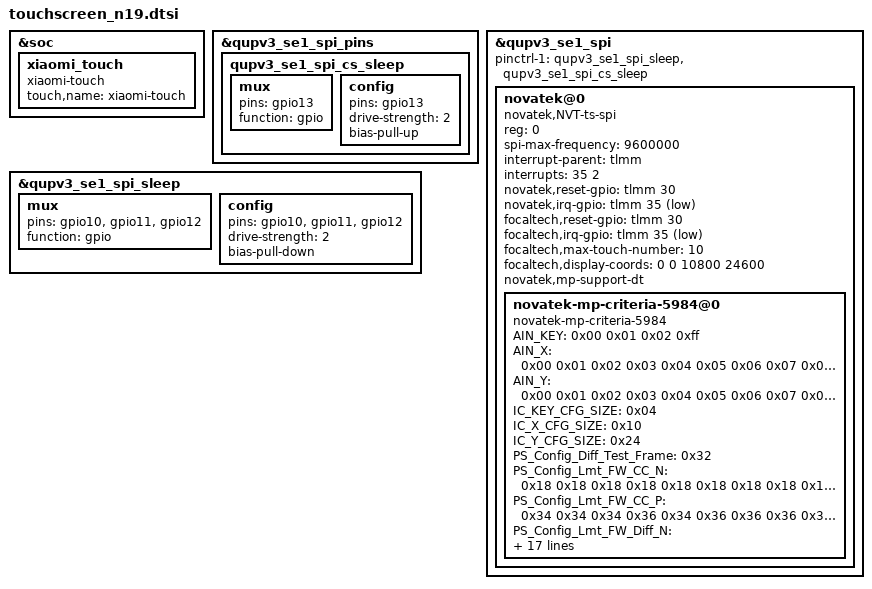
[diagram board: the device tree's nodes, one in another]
// SPDX-License-Identifier: BSD-3-Clause

&soc {
	xiaomi_touch {
		status = "ok";
		compatible = "xiaomi-touch";
		touch,name = "xiaomi-touch";
	};
};

&qupv3_se1_spi_pins {
	qupv3_se1_spi_cs_sleep: qupv3_se1_spi_cs_sleep {
		mux {
			pins = "gpio13";
			function = "gpio";
		};

		config {
			pins = "gpio13";
			drive-strength = <2>;
			bias-pull-up;
		};
	};
};

&qupv3_se1_spi_sleep {
	mux {
		pins = "gpio10", "gpio11", "gpio12";
		function = "gpio";
	};

	config {
		pins = "gpio10", "gpio11", "gpio12";
		drive-strength = <2>;
		bias-pull-down;
	};
};

/*
 * Stock has separate novatek@0 and focaltech@1 nodes, but both ICs sit on
 * CS0 and share the reset and interrupt GPIOs. Use one node so only one
 * driver binds at a time.
 */
&qupv3_se1_spi {
	#address-cells = <1>;
	#size-cells = <0>;
	pinctrl-1 = <&qupv3_se1_spi_sleep>, <&qupv3_se1_spi_cs_sleep>;
	status = "ok";

	novatek@0 {
		compatible = "novatek,NVT-ts-spi", "focaltech,fts";
		reg = <0>;
		status = "ok";
		spi-max-frequency = <9600000>;
		interrupt-parent = <&tlmm>;
		interrupts = <35 2>;
		novatek,reset-gpio = <&tlmm 30 0>;
		novatek,irq-gpio = <&tlmm 35 0x2001>;
		focaltech,reset-gpio = <&tlmm 30 0>;
		focaltech,irq-gpio = <&tlmm 35 0x2001>;
		focaltech,max-touch-number = <10>;
		focaltech,display-coords = <0 0 10800 24600>;
		novatek,mp-support-dt;

		novatek-mp-criteria-5984@0 {
			#address-cells = <0x01>;
			#size-cells = <0x00>;
			AIN_KEY = <0x00 0x01 0x02 0xff>;
			AIN_X = <0x00 0x01 0x02 0x03 0x04 0x05 0x06 0x07 0x08 0x09 0x0a 0x0b 0x0c 0x0d 0x0e 0x0f>;
			AIN_Y = <0x00 0x01 0x02 0x03 0x04 0x05 0x06 0x07 0x08 0x09 0x0a 0x0b 0x0c 0x0d 0x0e 0x0f 0x10 0x11 0x12 0x13 0x14 0x15 0x16 0x17 0x18 0x19 0x1a 0x1b 0x1c 0x1d 0x1e 0x1f 0x20 0x21 0x22 0x23>;
			IC_KEY_CFG_SIZE = <0x04>;
			IC_X_CFG_SIZE = <0x10>;
			IC_Y_CFG_SIZE = <0x24>;
			PS_Config_Diff_Test_Frame = <0x32>;
			PS_Config_Lmt_FW_CC_N = <0x18 0x18 0x18 0x18 0x18 0x18 0x18 0x18 0x18 0x18 0x18 0x18 0x18 0x18 0x18 0x18 0x18 0x18 0x18 0x18 0x18 0x18 0x18 0x18 0x18 0x18 0x18 0x18 0x18 0x18 0x18 0x18 0x18 0x18 0x18 0x18 0x18 0x18 0x18 0x18 0x18 0x18 0x18 0x18 0x18 0x18 0x18 0x18 0x18 0x18 0x18 0x18 0x18 0x18 0x18 0x18 0x18 0x18 0x18 0x18 0x18 0x18 0x18 0x18 0x18 0x18 0x18 0x18 0x18 0x18 0x18 0x18 0x18 0x18 0x18 0x18 0x18 0x18 0x18 0x18 0x18 0x18 0x18 0x18 0x18 0x18 0x18 0x18 0x18 0x18 0x18 0x18 0x18 0x18 0x18 0x18 0x18 0x18 0x18 0x18 0x18 0x18 0x18 0x18 0x18 0x18 0x18 0x18 0x18 0x18 0x18 0x18 0x18 0x18 0x18 0x18 0x18 0x18 0x18 0x18 0x18 0x18 0x18 0x18 0x18 0x18 0x18 0x18 0x18 0x18 0x18 0x18 0x18 0x18 0x18 0x18 0x18 0x18 0x18 0x18 0x18 0x18 0x18 0x18 0x18 0x18 0x18 0x18 0x18 0x18 0x18 0x18 0x18 0x18 0x18 0x18 0x18 0x18 0x18 0x18 0x18 0x18 0x18 0x18 0x18 0x18 0x18 0x18 0x18 0x18 0x18 0x18 0x18 0x18 0x18 0x18 0x18 0x18 0x18 0x18 0x18 0x18 0x18 0x18 0x18 0x18 0x18 0x18 0x18 0x18 0x18 0x18 0x18 0x18 0x18 0x18 0x18 0x18 0x18 0x18 0x18 0x18 0x18 0x18 0x18 0x18 0x18 0x18 0x18 0x18 0x18 0x18 0x18 0x18 0x18 0x18 0x18 0x18 0x18 0x18 0x18 0x18 0x18 0x18 0x18 0x18 0x18 0x18 0x18 0x18 0x18 0x18 0x18 0x18 0x18 0x18 0x18 0x18 0x18 0x18 0x18 0x18 0x18 0x18 0x18 0x18 0x18 0x18 0x18 0x18 0x18 0x18 0x18 0x18 0x18 0x18 0x18 0x18 0x18 0x18 0x18 0x18 0x18 0x18 0x18 0x18 0x18 0x18 0x18 0x18 0x18 0x19 0x18 0x18 0x18 0x18 0x18 0x18 0x18 0x19 0x18 0x18 0x18 0x18 0x18 0x18 0x18 0x18 0x18 0x18 0x18 0x18 0x18 0x18 0x18 0x18 0x18 0x18 0x18 0x18 0x18 0x18 0x18 0x18 0x18 0x18 0x18 0x18 0x18 0x18 0x18 0x18 0x18 0x18 0x18 0x18 0x18 0x18 0x18 0x18 0x18 0x18 0x18 0x18 0x18 0x18 0x18 0x18 0x18 0x18 0x18 0x18 0x18 0x18 0x18 0x18 0x19 0x18 0x18 0x18 0x18 0x18 0x18 0x18 0x18 0x18 0x18 0x18 0x18 0x18 0x18 0x19 0x18 0x18 0x18 0x18 0x18 0x18 0x18 0x18 0x18 0x18 0x18 0x18 0x18 0x18 0x18 0x19 0x19 0x18 0x18 0x18 0x18 0x18 0x18 0x18 0x18 0x18 0x18 0x18 0x18 0x18 0x18 0x18 0x18 0x18 0x18 0x18 0x18 0x18 0x18 0x18 0x18 0x18 0x18 0x18 0x18 0x18 0x18 0x18 0x19 0x18 0x18 0x18 0x18 0x18 0x18 0x18 0x18 0x18 0x18 0x18 0x18 0x18 0x18 0x18 0x18 0x18 0x18 0x18 0x18 0x18 0x18 0x18 0x18 0x18 0x18 0x18 0x18 0x18 0x18 0x18 0x19 0x18 0x18 0x18 0x18 0x18 0x18 0x18 0x18 0x18 0x18 0x18 0x18 0x18 0x18 0x19 0x18 0x18 0x18 0x18 0x18 0x18 0x18 0x18 0x18 0x18 0x18 0x18 0x18 0x18 0x18 0x19 0x19 0x18 0x18 0x18 0x18 0x18 0x18 0x18 0x18 0x18 0x18 0x18 0x18 0x18 0x18 0x19 0x18 0x18 0x18 0x18 0x18 0x18 0x18 0x18 0x18 0x18 0x18 0x18 0x18 0x18 0x18 0x19 0x19 0x18 0x18 0x18 0x18 0x18 0x18 0x18 0x18 0x18 0x18 0x18 0x18 0x18 0x18 0x19 0x18 0x18 0x18 0x18 0x18 0x18 0x18 0x18 0x18 0x18 0x18 0x18 0x18 0x18 0x18 0x19 0x19 0x18 0x18 0x18 0x18 0x18 0x18 0x18 0x18 0x18 0x18 0x18 0x18 0x18 0x18 0x19 0x18 0x18 0x18 0x18 0x18 0x18 0x18 0x18 0x18 0x18 0x18 0x18 0x18 0x18 0x18 0x18 0x18 0x18 0x18 0x18 0x18 0x18 0x18 0x19 0x19 0x18 0x18 0x18 0x18 0x18 0x18 0x18 0x00 0x00 0x00>;
			PS_Config_Lmt_FW_CC_P = <0x34 0x34 0x34 0x36 0x34 0x36 0x36 0x36 0x36 0x36 0x36 0x34 0x36 0x36 0x34 0x34 0x36 0x34 0x34 0x34 0x34 0x34 0x34 0x36 0x36 0x34 0x34 0x34 0x34 0x34 0x34 0x36 0x34 0x34 0x34 0x34 0x34 0x34 0x34 0x34 0x36 0x34 0x36 0x34 0x36 0x36 0x34 0x36 0x36 0x34 0x34 0x34 0x34 0x34 0x34 0x36 0x36 0x34 0x34 0x34 0x34 0x34 0x34 0x36 0x36 0x34 0x34 0x34 0x34 0x34 0x34 0x34 0x34 0x34 0x34 0x36 0x34 0x34 0x34 0x36 0x36 0x34 0x34 0x34 0x34 0x34 0x34 0x36 0x34 0x34 0x34 0x34 0x34 0x34 0x34 0x36 0x36 0x34 0x34 0x34 0x34 0x34 0x34 0x34 0x36 0x34 0x34 0x34 0x34 0x34 0x34 0x36 0x36 0x34 0x34 0x34 0x34 0x34 0x34 0x36 0x36 0x34 0x34 0x34 0x34 0x34 0x34 0x36 0x36 0x34 0x34 0x34 0x34 0x36 0x34 0x36 0x36 0x36 0x36 0x36 0x36 0x36 0x36 0x36 0x36 0x36 0x36 0x36 0x36 0x36 0x36 0x36 0x36 0x36 0x36 0x36 0x36 0x34 0x34 0x36 0x36 0x34 0x34 0x34 0x34 0x34 0x34 0x36 0x36 0x36 0x36 0x36 0x36 0x34 0x34 0x36 0x36 0x34 0x36 0x36 0x36 0x36 0x36 0x36 0x36 0x36 0x34 0x34 0x36 0x34 0x34 0x36 0x36 0x34 0x34 0x34 0x34 0x34 0x34 0x36 0x36 0x36 0x36 0x36 0x36 0x36 0x36 0x36 0x36 0x36 0x36 0x36 0x36 0x36 0x36 0x36 0x36 0x36 0x36 0x36 0x36 0x34 0x34 0x36 0x36 0x34 0x34 0x34 0x34 0x34 0x34 0x34 0x36 0x36 0x36 0x36 0x36 0x36 0x36 0x36 0x36 0x34 0x34 0x34 0x34 0x36 0x36 0x36 0x36 0x36 0x36 0x36 0x36 0x34 0x34 0x36 0x36 0x34 0x34 0x34 0x34 0x34 0x36 0x36 0x36 0x36 0x36 0x36 0x36 0x36 0x36 0x37 0x36 0x34 0x36 0x36 0x36 0x36 0x36 0x37 0x34 0x36 0x36 0x34 0x34 0x34 0x34 0x36 0x36 0x34 0x34 0x34 0x34 0x34 0x34 0x34 0x36 0x36 0x36 0x34 0x36 0x34 0x34 0x36 0x36 0x34 0x34 0x34 0x34 0x34 0x34 0x34 0x36 0x36 0x36 0x34 0x36 0x34 0x34 0x36 0x36 0x34 0x34 0x34 0x34 0x34 0x36 0x34 0x36 0x36 0x36 0x36 0x36 0x36 0x36 0x36 0x37 0x36 0x36 0x36 0x36 0x36 0x36 0x36 0x36 0x36 0x36 0x36 0x36 0x36 0x36 0x37 0x36 0x34 0x34 0x34 0x34 0x34 0x34 0x34 0x36 0x36 0x36 0x36 0x36 0x36 0x36 0x37 0x37 0x36 0x36 0x36 0x36 0x36 0x36 0x36 0x36 0x36 0x36 0x36 0x36 0x36 0x36 0x36 0x36 0x34 0x34 0x34 0x34 0x34 0x36 0x36 0x36 0x36 0x36 0x36 0x36 0x36 0x36 0x36 0x37 0x36 0x36 0x36 0x36 0x36 0x36 0x36 0x36 0x36 0x36 0x36 0x36 0x36 0x36 0x36 0x36 0x34 0x36 0x34 0x34 0x34 0x36 0x36 0x36 0x36 0x36 0x36 0x36 0x36 0x36 0x36 0x37 0x36 0x36 0x36 0x36 0x36 0x36 0x36 0x36 0x36 0x36 0x36 0x36 0x36 0x36 0x37 0x36 0x36 0x36 0x36 0x36 0x36 0x36 0x36 0x36 0x36 0x36 0x36 0x36 0x36 0x36 0x37 0x37 0x36 0x36 0x36 0x36 0x36 0x36 0x36 0x36 0x36 0x36 0x36 0x36 0x36 0x36 0x37 0x36 0x34 0x36 0x34 0x34 0x34 0x34 0x34 0x36 0x36 0x36 0x36 0x36 0x36 0x36 0x37 0x37 0x36 0x36 0x36 0x36 0x36 0x36 0x36 0x36 0x36 0x36 0x36 0x36 0x36 0x36 0x37 0x36 0x36 0x36 0x34 0x36 0x34 0x36 0x34 0x36 0x36 0x36 0x36 0x36 0x36 0x36 0x37 0x37 0x36 0x36 0x36 0x36 0x36 0x36 0x36 0x36 0x36 0x36 0x36 0x36 0x36 0x36 0x37 0x36 0x34 0x36 0x34 0x34 0x34 0x34 0x34 0x36 0x36 0x34 0x34 0x36 0x36 0x36 0x36 0x36 0x34 0x36 0x36 0x36 0x36 0x36 0x37 0x37 0x36 0x36 0x36 0x36 0x36 0x36 0x36 0x13a 0x13a 0x13a>;
			PS_Config_Lmt_FW_Diff_N = <0xffffffce 0xffffffce 0xffffffce 0xffffffce 0xffffffce 0xffffffce 0xffffffce 0xffffffce 0xffffffce 0xffffffce 0xffffffce 0xffffffce 0xffffffce 0xffffffce 0xffffffce 0xffffffce 0xffffffce 0xffffffce 0xffffffce 0xffffffce 0xffffffce 0xffffffce 0xffffffce 0xffffffce 0xffffffce 0xffffffce 0xffffffce 0xffffffce 0xffffffce 0xffffffce 0xffffffce 0xffffffce 0xffffffce 0xffffffce 0xffffffce 0xffffffce 0xffffffce 0xffffffce 0xffffffce 0xffffffce 0xffffffce 0xffffffce 0xffffffce 0xffffffce 0xffffffce 0xffffffce 0xffffffce 0xffffffce 0xffffffce 0xffffffce 0xffffffce 0xffffffce 0xffffffce 0xffffffce 0xffffffce 0xffffffce 0xffffffce 0xffffffce 0xffffffce 0xffffffce 0xffffffce 0xffffffce 0xffffffce 0xffffffce 0xffffffce 0xffffffce 0xffffffce 0xffffffce 0xffffffce 0xffffffce 0xffffffce 0xffffffce 0xffffffce 0xffffffce 0xffffffce 0xffffffce 0xffffffce 0xffffffce 0xffffffce 0xffffffce 0xffffffce 0xffffffce 0xffffffce 0xffffffce 0xffffffce 0xffffffce 0xffffffce 0xffffffce 0xffffffce 0xffffffce 0xffffffce 0xffffffce 0xffffffce 0xffffffce 0xffffffce 0xffffffce 0xffffffce 0xffffffce 0xffffffce 0xffffffce 0xffffffce 0xffffffce 0xffffffce 0xffffffce 0xffffffce 0xffffffce 0xffffffce 0xffffffce 0xffffffce 0xffffffce 0xffffffce 0xffffffce 0xffffffce 0xffffffce 0xffffffce 0xffffffce 0xffffffce 0xffffffce 0xffffffce 0xffffffce 0xffffffce 0xffffffce 0xffffffce 0xffffffce 0xffffffce 0xffffffce 0xffffffce 0xffffffce 0xffffffce 0xffffffce 0xffffffce 0xffffffce 0xffffffce 0xffffffce 0xffffffce 0xffffffce 0xffffffce 0xffffffce 0xffffffce 0xffffffce 0xffffffce 0xffffffce 0xffffffce 0xffffffce 0xffffffce 0xffffffce 0xffffffce 0xffffffce 0xffffffce 0xffffffce 0xffffffce 0xffffffce 0xffffffce 0xffffffce 0xffffffce 0xffffffce 0xffffffce 0xffffffce 0xffffffce 0xffffffce 0xffffffce 0xffffffce 0xffffffce 0xffffffce 0xffffffce 0xffffffce 0xffffffce 0xffffffce 0xffffffce 0xffffffce 0xffffffce 0xffffffce 0xffffffce 0xffffffce 0xffffffce 0xffffffce 0xffffffce 0xffffffce 0xffffffce 0xffffffce 0xffffffce 0xffffffce 0xffffffce 0xffffffce 0xffffffce 0xffffffce 0xffffffce 0xffffffce 0xffffffce 0xffffffce 0xffffffce 0xffffffce 0xffffffce 0xffffffce 0xffffffce 0xffffffce 0xffffffce 0xffffffce 0xffffffce 0xffffffce 0xffffffce 0xffffffce 0xffffffce 0xffffffce 0xffffffce 0xffffffce 0xffffffce 0xffffffce 0xffffffce 0xffffffce 0xffffffce 0xffffffce 0xffffffce 0xffffffce 0xffffffce 0xffffffce 0xffffffce 0xffffffce 0xffffffce 0xffffffce 0xffffffce 0xffffffce 0xffffffce 0xffffffce 0xffffffce 0xffffffce 0xffffffce 0xffffffce 0xffffffce 0xffffffce 0xffffffce 0xffffffce 0xffffffce 0xffffffce 0xffffffce 0xffffffce 0xffffffce 0xffffffce 0xffffffce 0xffffffce 0xffffffce 0xffffffce 0xffffffce 0xffffffce 0xffffffce 0xffffffce 0xffffffce 0xffffffce 0xffffffce 0xffffffce 0xffffffce 0xffffffce 0xffffffce 0xffffffce 0xffffffce 0xffffffce 0xffffffce 0xffffffce 0xffffffce 0xffffffce 0xffffffce 0xffffffce 0xffffffce 0xffffffce 0xffffffce 0xffffffce 0xffffffce 0xffffffce 0xffffffce 0xffffffce 0xffffffce 0xffffffce 0xffffffce 0xffffffce 0xffffffce 0xffffffce 0xffffffce 0xffffffce 0xffffffce 0xffffffce 0xffffffce 0xffffffce 0xffffffce 0xffffffce 0xffffffce 0xffffffce 0xffffffce 0xffffffce 0xffffffce 0xffffffce 0xffffffce 0xffffffce 0xffffffce 0xffffffce 0xffffffce 0xffffffce 0xffffffce 0xffffffce 0xffffffce 0xffffffce 0xffffffce 0xffffffce 0xffffffce 0xffffffce 0xffffffce 0xffffffce 0xffffffce 0xffffffce 0xffffffce 0xffffffce 0xffffffce 0xffffffce 0xffffffce 0xffffffce 0xffffffce 0xffffffce 0xffffffce 0xffffffce 0xffffffce 0xffffffce 0xffffffce 0xffffffce 0xffffffce 0xffffffce 0xffffffce 0xffffffce 0xffffffce 0xffffffce 0xffffffce 0xffffffce 0xffffffce 0xffffffce 0xffffffce 0xffffffce 0xffffffce 0xffffffce 0xffffffce 0xffffffce 0xffffffce 0xffffffce 0xffffffce 0xffffffce 0xffffffce 0xffffffce 0xffffffce 0xffffffce 0xffffffce 0xffffffce 0xffffffce 0xffffffce 0xffffffce 0xffffffce 0xffffffce 0xffffffce 0xffffffce 0xffffffce 0xffffffce 0xffffffce 0xffffffce 0xffffffce 0xffffffce 0xffffffce 0xffffffce 0xffffffce 0xffffffce 0xffffffce 0xffffffce 0xffffffce 0xffffffce 0xffffffce 0xffffffce 0xffffffce 0xffffffce 0xffffffce 0xffffffce 0xffffffce 0xffffffce 0xffffffce 0xffffffce 0xffffffce 0xffffffce 0xffffffce 0xffffffce 0xffffffce 0xffffffce 0xffffffce 0xffffffce 0xffffffce 0xffffffce 0xffffffce 0xffffffce 0xffffffce 0xffffffce 0xffffffce 0xffffffce 0xffffffce 0xffffffce 0xffffffce 0xffffffce 0xffffffce 0xffffffce 0xffffffce 0xffffffce 0xffffffce 0xffffffce 0xffffffce 0xffffffce 0xffffffce 0xffffffce 0xffffffce 0xffffffce 0xffffffce 0xffffffce 0xffffffce 0xffffffce 0xffffffce 0xffffffce 0xffffffce 0xffffffce 0xffffffce 0xffffffce 0xffffffce 0xffffffce 0xffffffce 0xffffffce 0xffffffce 0xffffffce 0xffffffce 0xffffffce 0xffffffce 0xffffffce 0xffffffce 0xffffffce 0xffffffce 0xffffffce 0xffffffce 0xffffffce 0xffffffce 0xffffffce 0xffffffce 0xffffffce 0xffffffce 0xffffffce 0xffffffce 0xffffffce 0xffffffce 0xffffffce 0xffffffce 0xffffffce 0xffffffce 0xffffffce 0xffffffce 0xffffffce 0xffffffce 0xffffffce 0xffffffce 0xffffffce 0xffffffce 0xffffffce 0xffffffce 0xffffffce 0xffffffce 0xffffffce 0xffffffce 0xffffffce 0xffffffce 0xffffffce 0xffffffce 0xffffffce 0xffffffce 0xffffffce 0xffffffce 0xffffffce 0xffffffce 0xffffffce 0xffffffce 0xffffffce 0xffffffce 0xffffffce 0xffffffce 0xffffffce 0xffffffce 0xffffffce 0xffffffce 0xffffffce 0xffffffce 0xffffffce 0xffffffce 0xffffffce 0xffffffce 0xffffffce 0xffffffce 0xffffffce 0xffffffce 0xffffffce 0xffffffce 0xffffffce 0xffffffce 0xffffffce 0xffffffce 0xffffffce 0xffffffce 0xffffffce 0xffffffce 0xffffffce 0xffffffce 0xffffffce 0xffffffce 0xffffffce 0xffffffce 0xffffffce 0xffffffce 0xffffffce 0xffffffce 0xffffffce 0xffffffce 0xffffffce 0xffffffce 0xffffffce 0xffffffce 0xffffffce 0xffffffce 0xffffffce 0xffffffce 0xffffffce 0xffffffce 0xffffffce 0xffffffce 0xffffffce 0xffffffce 0xffffffce 0xffffffce 0xffffffce 0xffffffce 0xffffffce 0xffffffce 0xffffffce 0xffffffce 0xffffffce 0xffffffce 0xffffffce 0xffffffce 0xffffffce 0xffffffce 0xffffffce 0xffffffce 0xffffffce 0xffffffce 0xffffffce 0xffffffce 0xffffffce 0xffffffce 0xffffffce 0xffffffce 0xffffffce 0xffffffce 0xffffffce 0xffffffce 0xffffffce 0xffffffce 0xffffffce 0xffffffce 0xffffffce 0xffffffce 0xffffffce 0xffffffce 0xffffffce 0xffffffce 0xffffffce 0xffffffce 0xffffffce 0xffffffce 0xffffffce 0xffffffce 0xffffffce 0xffffffce 0xffffffb5 0xffffffb5 0xffffffb5>;
			PS_Config_Lmt_FW_Diff_P = <0x32 0x32 0x32 0x32 0x32 0x32 0x32 0x32 0x32 0x32 0x32 0x32 0x32 0x32 0x32 0x32 0x32 0x32 0x32 0x32 0x32 0x32 0x32 0x32 0x32 0x32 0x32 0x32 0x32 0x32 0x32 0x32 0x32 0x32 0x32 0x32 0x32 0x32 0x32 0x32 0x32 0x32 0x32 0x32 0x32 0x32 0x32 0x32 0x32 0x32 0x32 0x32 0x32 0x32 0x32 0x32 0x32 0x32 0x32 0x32 0x32 0x32 0x32 0x32 0x32 0x32 0x32 0x32 0x32 0x32 0x32 0x32 0x32 0x32 0x32 0x32 0x32 0x32 0x32 0x32 0x32 0x32 0x32 0x32 0x32 0x32 0x32 0x32 0x32 0x32 0x32 0x32 0x32 0x32 0x32 0x32 0x32 0x32 0x32 0x32 0x32 0x32 0x32 0x32 0x32 0x32 0x32 0x32 0x32 0x32 0x32 0x32 0x32 0x32 0x32 0x32 0x32 0x32 0x32 0x32 0x32 0x32 0x32 0x32 0x32 0x32 0x32 0x32 0x32 0x32 0x32 0x32 0x32 0x32 0x32 0x32 0x32 0x32 0x32 0x32 0x32 0x32 0x32 0x32 0x32 0x32 0x32 0x32 0x32 0x32 0x32 0x32 0x32 0x32 0x32 0x32 0x32 0x32 0x32 0x32 0x32 0x32 0x32 0x32 0x32 0x32 0x32 0x32 0x32 0x32 0x32 0x32 0x32 0x32 0x32 0x32 0x32 0x32 0x32 0x32 0x32 0x32 0x32 0x32 0x32 0x32 0x32 0x32 0x32 0x32 0x32 0x32 0x32 0x32 0x32 0x32 0x32 0x32 0x32 0x32 0x32 0x32 0x32 0x32 0x32 0x32 0x32 0x32 0x32 0x32 0x32 0x32 0x32 0x32 0x32 0x32 0x32 0x32 0x32 0x32 0x32 0x32 0x32 0x32 0x32 0x32 0x32 0x32 0x32 0x32 0x32 0x32 0x32 0x32 0x32 0x32 0x32 0x32 0x32 0x32 0x32 0x32 0x32 0x32 0x32 0x32 0x32 0x32 0x32 0x32 0x32 0x32 0x32 0x32 0x32 0x32 0x32 0x32 0x32 0x32 0x32 0x32 0x32 0x32 0x32 0x32 0x32 0x32 0x32 0x32 0x32 0x32 0x32 0x32 0x32 0x32 0x32 0x32 0x32 0x32 0x32 0x32 0x32 0x32 0x32 0x32 0x32 0x32 0x32 0x32 0x32 0x32 0x32 0x32 0x32 0x32 0x32 0x32 0x32 0x32 0x32 0x32 0x32 0x32 0x32 0x32 0x32 0x32 0x32 0x32 0x32 0x32 0x32 0x32 0x32 0x32 0x32 0x32 0x32 0x32 0x32 0x32 0x32 0x32 0x32 0x32 0x32 0x32 0x32 0x32 0x32 0x32 0x32 0x32 0x32 0x32 0x32 0x32 0x32 0x32 0x32 0x32 0x32 0x32 0x32 0x32 0x32 0x32 0x32 0x32 0x32 0x32 0x32 0x32 0x32 0x32 0x32 0x32 0x32 0x32 0x32 0x32 0x32 0x32 0x32 0x32 0x32 0x32 0x32 0x32 0x32 0x32 0x32 0x32 0x32 0x32 0x32 0x32 0x32 0x32 0x32 0x32 0x32 0x32 0x32 0x32 0x32 0x32 0x32 0x32 0x32 0x32 0x32 0x32 0x32 0x32 0x32 0x32 0x32 0x32 0x32 0x32 0x32 0x32 0x32 0x32 0x32 0x32 0x32 0x32 0x32 0x32 0x32 0x32 0x32 0x32 0x32 0x32 0x32 0x32 0x32 0x32 0x32 0x32 0x32 0x32 0x32 0x32 0x32 0x32 0x32 0x32 0x32 0x32 0x32 0x32 0x32 0x32 0x32 0x32 0x32 0x32 0x32 0x32 0x32 0x32 0x32 0x32 0x32 0x32 0x32 0x32 0x32 0x32 0x32 0x32 0x32 0x32 0x32 0x32 0x32 0x32 0x32 0x32 0x32 0x32 0x32 0x32 0x32 0x32 0x32 0x32 0x32 0x32 0x32 0x32 0x32 0x32 0x32 0x32 0x32 0x32 0x32 0x32 0x32 0x32 0x32 0x32 0x32 0x32 0x32 0x32 0x32 0x32 0x32 0x32 0x32 0x32 0x32 0x32 0x32 0x32 0x32 0x32 0x32 0x32 0x32 0x32 0x32 0x32 0x32 0x32 0x32 0x32 0x32 0x32 0x32 0x32 0x32 0x32 0x32 0x32 0x32 0x32 0x32 0x32 0x32 0x32 0x32 0x32 0x32 0x32 0x32 0x32 0x32 0x32 0x32 0x32 0x32 0x32 0x32 0x32 0x32 0x32 0x32 0x32 0x32 0x32 0x32 0x32 0x32 0x32 0x32 0x32 0x32 0x32 0x32 0x32 0x32 0x32 0x32 0x32 0x32 0x32 0x32 0x32 0x32 0x32 0x32 0x32 0x32 0x32 0x32 0x32 0x32 0x32 0x4b 0x4b 0x4b>;
			PS_Config_Lmt_FW_Rawdata_N = <0x1e0 0x1d7 0x1d6 0x1df 0x1d9 0x1de 0x1e1 0x1e5 0x1d7 0x1d1 0x1d3 0x1e1 0x1d2 0x1dc 0x1e5 0x1d8 0x1db 0x1db 0x1d9 0x1dc 0x1d8 0x1de 0x1db 0x1e2 0x1d7 0x1da 0x1dc 0x1d8 0x1de 0x1da 0x1d9 0x1e0 0x1db 0x1e2 0x1e5 0x1df 0x1e1 0x1df 0x1d6 0x1cf 0x1db 0x1dd 0x1db 0x1df 0x1da 0x1d9 0x1dd 0x1d9 0x1d9 0x1e2 0x1e4 0x1e1 0x1df 0x1e4 0x1e4 0x1da 0x1e2 0x1e2 0x1e1 0x1de 0x1e4 0x1e5 0x1e1 0x1d9 0x1db 0x1d6 0x1d8 0x1d9 0x1d9 0x1d9 0x1da 0x1dd 0x1d5 0x1dc 0x1d6 0x1d2 0x1d2 0x1db 0x1e6 0x1da 0x1e5 0x1e4 0x1de 0x1dc 0x1dc 0x1dc 0x1db 0x1d8 0x1db 0x1d4 0x1d8 0x1d4 0x1d5 0x1d3 0x1d0 0x1dc 0x1db 0x1d7 0x1d5 0x1d6 0x1d7 0x1d6 0x1db 0x1d7 0x1d9 0x1dd 0x1dc 0x1dc 0x1d9 0x1d9 0x1db 0x1d9 0x1e0 0x1db 0x1d5 0x1db 0x1df 0x1da 0x1e1 0x1d5 0x1e1 0x1e2 0x1e3 0x1df 0x1dd 0x1dd 0x1de 0x1d8 0x1d4 0x1e3 0x1da 0x1d5 0x1d6 0x1d5 0x1d8 0x1d7 0x1db 0x1d8 0x1d9 0x1de 0x1e2 0x1df 0x1e2 0x1db 0x1d3 0x1d9 0x1d7 0x1d2 0x1d3 0x1da 0x1d9 0x1dc 0x1dc 0x1da 0x1db 0x1d9 0x1d7 0x1d6 0x1dc 0x1de 0x1d8 0x1de 0x1e8 0x1e5 0x1e1 0x1e5 0x1e5 0x1d9 0x1e3 0x1e1 0x1de 0x1e0 0x1df 0x1e2 0x1de 0x1de 0x1dc 0x1d7 0x1d0 0x1d3 0x1d6 0x1db 0x1d9 0x1df 0x1df 0x1e3 0x1e5 0x1e7 0x1e2 0x1e8 0x1ea 0x1e2 0x1e1 0x1db 0x1d9 0x1dc 0x1d7 0x1de 0x1dd 0x1dc 0x1e3 0x1e2 0x1dc 0x1d9 0x1de 0x1d7 0x1d5 0x1d6 0x1e1 0x1d1 0x1d0 0x1d5 0x1d8 0x1d7 0x1d7 0x1e5 0x1d7 0x1dc 0x1e2 0x1e6 0x1e4 0x1e1 0x1df 0x1df 0x1e2 0x1e2 0x1e1 0x1dd 0x1e4 0x1d6 0x1d5 0x1da 0x1df 0x1e0 0x1d3 0x1d3 0x1db 0x1d3 0x1d7 0x1e1 0x1dc 0x1d6 0x1db 0x1df 0x1de 0x1e2 0x1de 0x1da 0x1e1 0x1e1 0x1e1 0x1db 0x1e2 0x1d3 0x1d4 0x1de 0x1d5 0x1da 0x1db 0x1db 0x1de 0x1e2 0x1df 0x1e5 0x1cf 0x1d2 0x1d9 0x1db 0x1d9 0x1db 0x1de 0x1d7 0x1dd 0x1e7 0x1de 0x1d5 0x1d5 0x1d4 0x1dc 0x1d0 0x1d7 0x1db 0x1e2 0x1d5 0x1d6 0x1d5 0x1df 0x1dd 0x1e5 0x1de 0x1d9 0x1d7 0x1d9 0x1d3 0x1d5 0x1d6 0x1df 0x1e7 0x1e2 0x1e4 0x1e2 0x1e2 0x1e2 0x1e1 0x1e6 0x1dd 0x1db 0x1db 0x1df 0x1d8 0x1d6 0x1d6 0x1e0 0x1dc 0x1dc 0x1dc 0x1db 0x1de 0x1e1 0x1da 0x1d9 0x1d0 0x1d2 0x1d4 0x1ce 0x1d3 0x1da 0x1d8 0x1de 0x1d2 0x1d5 0x1c9 0x1d4 0x1cd 0x1d2 0x1e5 0x1e5 0x1df 0x1dc 0x1dc 0x1db 0x1db 0x1e1 0x1e1 0x1e1 0x1d8 0x1db 0x1df 0x1e1 0x1e9 0x1e5 0x1de 0x1d4 0x1d5 0x1d7 0x1d8 0x1d6 0x1d0 0x1e2 0x1e4 0x1e7 0x1e2 0x1e4 0x1dc 0x1df 0x1df 0x1d9 0x1df 0x1d6 0x1d0 0x1d6 0x1d6 0x1d6 0x1cf 0x1d8 0x1d9 0x1e1 0x1d8 0x1d8 0x1d5 0x1d8 0x1d5 0x1d5 0x1e7 0x1de 0x1e0 0x1e3 0x1e1 0x1e0 0x1d6 0x1e5 0x1e4 0x1dc 0x1d8 0x1d8 0x1d8 0x1d5 0x1d6 0x1d5 0x1e5 0x1e4 0x1e7 0x1e3 0x1e0 0x1e0 0x1db 0x1dd 0x1e2 0x1d4 0x1e7 0x1e6 0x1e0 0x1e2 0x1e2 0x1e4 0x1d9 0x1e2 0x1dc 0x1d8 0x1dc 0x1d5 0x1d9 0x1d5 0x1d3 0x1e1 0x1e2 0x1e4 0x1e2 0x1e2 0x1e5 0x1e1 0x1d2 0x1e2 0x1df 0x1db 0x1e5 0x1ea 0x1e4 0x1e1 0x1e7 0x1e1 0x1dc 0x1d9 0x1de 0x1d9 0x1db 0x1de 0x1db 0x1da 0x1dc 0x1d9 0x1df 0x1de 0x1de 0x1e2 0x1df 0x1df 0x1e1 0x1de 0x1e1 0x1db 0x1e2 0x1d8 0x1dc 0x1e5 0x1e8 0x1e4 0x1e7 0x1e5 0x1e1 0x1e5 0x1e0 0x1e2 0x1de 0x1dd 0x1dd 0x1dd 0x1e4 0x1e4 0x1db 0x1dc 0x1e1 0x1de 0x1dc 0x1db 0x1db 0x1dc 0x1de 0x1df 0x1df 0x1df 0x1db 0x1e1 0x1e1 0x1de 0x1df 0x1e0 0x1d6 0x1d6 0x1e0 0x1d3 0x1e1 0x1e7 0x1e1 0x1db 0x1d9 0x1d3 0x1d5 0x1d7 0x1dc 0x1dc 0x1df 0x1d5 0x1d8 0x1e7 0x1d2 0x1da 0x1d8 0x1d9 0x1dd 0x1d8 0x1d9 0x1d8 0x1d9 0x1d6 0x1d8 0x1d5 0x1d9 0x1e2 0x1d6 0x1e8 0x1cf 0x1d5 0x1d0 0x1da 0x1dd 0x1dd 0x1dc 0x1d9 0x1d6 0x1d0 0x1db 0x1db 0x1d9 0x1d4 0x1d8 0x1df 0x1dc 0x1d4 0x1db 0x1da 0x1de 0x1db 0x1d3 0x1e6 0x1e2 0x1e0 0x1cf 0x1cf 0x1e5 0x1d7 0x1d3 0x1d8 0x1db 0x1e4 0x1db 0x1e1 0x1df 0x1d7 0x1e0 0x1ea 0x1de 0x1e2 0x1dc 0x1d6 0x1da 0xf0 0xf0 0xf0>;
			PS_Config_Lmt_FW_Rawdata_P = <0x460 0x44b 0x448 0x45f 0x44f 0x45c 0x461 0x46b 0x44b 0x43d 0x441 0x461 0x440 0x458 0x46b 0x44c 0x453 0x453 0x44f 0x456 0x44c 0x45a 0x453 0x464 0x44b 0x452 0x456 0x44c 0x45c 0x452 0x451 0x460 0x453 0x466 0x46b 0x45d 0x463 0x45f 0x44a 0x439 0x453 0x459 0x455 0x45f 0x452 0x44f 0x459 0x44f 0x451 0x464 0x468 0x463 0x45d 0x46a 0x46a 0x452 0x464 0x466 0x463 0x45c 0x468 0x46b 0x463 0x451 0x453 0x44a 0x44c 0x44f 0x451 0x451 0x452 0x459 0x447 0x456 0x448 0x43e 0x440 0x455 0x46e 0x452 0x46b 0x46a 0x45a 0x456 0x456 0x458 0x455 0x44e 0x453 0x444 0x44c 0x444 0x447 0x443 0x43c 0x458 0x455 0x44b 0x445 0x448 0x44b 0x448 0x455 0x44b 0x451 0x459 0x458 0x456 0x44f 0x44f 0x455 0x451 0x460 0x453 0x445 0x453 0x45f 0x452 0x463 0x445 0x461 0x466 0x467 0x45f 0x459 0x459 0x45a 0x44e 0x444 0x467 0x452 0x447 0x448 0x445 0x44e 0x44b 0x453 0x44e 0x451 0x45a 0x464 0x45d 0x466 0x455 0x441 0x451 0x44b 0x440 0x441 0x452 0x44f 0x458 0x458 0x452 0x453 0x44f 0x44b 0x44a 0x456 0x45a 0x44c 0x45a 0x474 0x46d 0x463 0x46d 0x46b 0x451 0x467 0x461 0x45a 0x460 0x45f 0x466 0x45a 0x45c 0x458 0x44b 0x43a 0x443 0x448 0x455 0x44f 0x45f 0x45d 0x467 0x46d 0x471 0x464 0x474 0x478 0x466 0x463 0x455 0x451 0x456 0x44b 0x45a 0x459 0x458 0x467 0x466 0x456 0x44f 0x45c 0x44b 0x447 0x44a 0x463 0x43d 0x43c 0x445 0x44c 0x44b 0x44b 0x46b 0x44b 0x456 0x464 0x46e 0x46a 0x463 0x45f 0x45d 0x466 0x466 0x461 0x459 0x46a 0x44a 0x445 0x452 0x45f 0x460 0x441 0x441 0x453 0x441 0x44b 0x463 0x456 0x44a 0x455 0x45d 0x45a 0x464 0x45a 0x452 0x461 0x463 0x463 0x453 0x466 0x441 0x444 0x45a 0x445 0x452 0x455 0x455 0x45a 0x466 0x45f 0x46b 0x439 0x43e 0x44f 0x453 0x451 0x453 0x45a 0x44b 0x459 0x471 0x45c 0x447 0x447 0x444 0x456 0x43a 0x44b 0x453 0x466 0x447 0x448 0x445 0x45f 0x459 0x46d 0x45c 0x451 0x44b 0x44f 0x443 0x445 0x448 0x45f 0x471 0x466 0x46a 0x466 0x466 0x464 0x461 0x46e 0x459 0x455 0x453 0x45d 0x44c 0x448 0x44a 0x460 0x456 0x458 0x456 0x453 0x45a 0x461 0x452 0x44f 0x43c 0x43e 0x444 0x436 0x441 0x452 0x44e 0x45c 0x43e 0x447 0x429 0x444 0x433 0x440 0x46d 0x46d 0x45f 0x456 0x456 0x453 0x453 0x463 0x463 0x463 0x44e 0x453 0x45f 0x461 0x475 0x46b 0x45c 0x444 0x445 0x44b 0x44c 0x44a 0x43a 0x466 0x46a 0x471 0x466 0x46a 0x458 0x45d 0x45d 0x451 0x45f 0x44a 0x43c 0x448 0x448 0x448 0x439 0x44e 0x451 0x463 0x44e 0x44c 0x447 0x44c 0x445 0x445 0x471 0x45a 0x460 0x467 0x463 0x460 0x448 0x46b 0x46a 0x458 0x44c 0x44e 0x44e 0x445 0x448 0x447 0x46d 0x468 0x46f 0x467 0x460 0x460 0x453 0x459 0x464 0x444 0x471 0x46e 0x460 0x466 0x466 0x46a 0x451 0x464 0x456 0x44e 0x458 0x447 0x451 0x445 0x441 0x461 0x464 0x468 0x466 0x466 0x46b 0x461 0x43e 0x464 0x45f 0x455 0x46d 0x476 0x468 0x463 0x46f 0x461 0x458 0x44f 0x45a 0x44f 0x455 0x45c 0x455 0x452 0x458 0x451 0x45d 0x45a 0x45c 0x464 0x45d 0x45d 0x461 0x45a 0x461 0x453 0x464 0x44e 0x458 0x46d 0x472 0x46a 0x46f 0x46d 0x463 0x46d 0x460 0x464 0x45a 0x459 0x459 0x459 0x468 0x46a 0x455 0x456 0x463 0x45c 0x456 0x453 0x453 0x458 0x45c 0x45d 0x45f 0x45d 0x455 0x463 0x463 0x45a 0x45f 0x460 0x44a 0x448 0x460 0x443 0x463 0x471 0x463 0x455 0x44f 0x443 0x445 0x44b 0x458 0x456 0x45f 0x447 0x44e 0x46f 0x440 0x452 0x44e 0x451 0x459 0x44c 0x451 0x44c 0x451 0x448 0x44c 0x447 0x451 0x464 0x44a 0x472 0x437 0x447 0x43c 0x452 0x459 0x459 0x456 0x44f 0x448 0x43c 0x453 0x455 0x44f 0x444 0x44c 0x45d 0x458 0x444 0x455 0x452 0x45a 0x455 0x443 0x46e 0x464 0x460 0x439 0x439 0x46b 0x44b 0x443 0x44e 0x455 0x46a 0x453 0x463 0x45d 0x44b 0x460 0x476 0x45c 0x466 0x458 0x44a 0x452 0xf00 0xf00 0xf00>;
			PS_Config_Lmt_Open_Rawdata_N = <0x49f 0x4be 0x4e2 0x500 0x508 0x50b 0x51e 0x4ca 0x4bb 0x4fb 0x4f8 0x4f6 0x4fa 0x4df 0x4c2 0x4ac 0x4b6 0x4cd 0x4f0 0x509 0x517 0x51a 0x52a 0x4ff 0x4e6 0x50a 0x507 0x503 0x509 0x4f0 0x4d5 0x4cc 0x4ca 0x4e4 0x50a 0x526 0x533 0x533 0x545 0x52f 0x511 0x51e 0x51e 0x51a 0x521 0x500 0x4ea 0x4db 0x4cc 0x4eb 0x512 0x52d 0x53b 0x53b 0x54e 0x536 0x509 0x520 0x521 0x51e 0x524 0x506 0x4ef 0x4e6 0x4e9 0x502 0x526 0x544 0x553 0x553 0x561 0x54a 0x531 0x538 0x535 0x531 0x534 0x515 0x4ff 0x4f5 0x4f7 0x509 0x52c 0x54c 0x55e 0x55b 0x566 0x550 0x53f 0x542 0x53e 0x53b 0x53e 0x51e 0x508 0x503 0x4f9 0x50d 0x536 0x552 0x566 0x565 0x572 0x557 0x548 0x544 0x546 0x53e 0x53f 0x520 0x506 0x502 0x500 0x50a 0x53c 0x557 0x572 0x571 0x57d 0x562 0x55d 0x54a 0x556 0x54f 0x54e 0x52d 0x514 0x514 0x512 0x52b 0x550 0x56b 0x589 0x583 0x593 0x574 0x582 0x575 0x574 0x56d 0x569 0x547 0x530 0x52e 0x524 0x53a 0x55b 0x578 0x597 0x590 0x5a4 0x581 0x588 0x57a 0x576 0x571 0x569 0x547 0x52f 0x533 0x526 0x542 0x554 0x57f 0x59e 0x598 0x5a8 0x589 0x598 0x58c 0x579 0x580 0x571 0x550 0x536 0x53b 0x533 0x550 0x56e 0x58a 0x5aa 0x5a5 0x5b6 0x593 0x5a5 0x598 0x590 0x589 0x57b 0x558 0x53e 0x548 0x53e 0x55d 0x580 0x596 0x5bd 0x5b9 0x5c6 0x59e 0x5ac 0x5a0 0x59e 0x58f 0x581 0x562 0x545 0x54d 0x54a 0x568 0x58c 0x59b 0x5c4 0x5c0 0x5d1 0x5a4 0x5c2 0x5b4 0x5b1 0x5a1 0x58e 0x56d 0x553 0x55f 0x549 0x56c 0x590 0x595 0x5c7 0x5c3 0x5d5 0x5a5 0x5cf 0x5bd 0x5b8 0x59c 0x596 0x56f 0x559 0x561 0x554 0x577 0x599 0x5a9 0x5d1 0x5cb 0x5e2 0x5b1 0x5d5 0x5c1 0x5c0 0x5ae 0x595 0x56f 0x55b 0x569 0x55c 0x587 0x5a7 0x5b7 0x5de 0x5dc 0x5f3 0x5bf 0x5e9 0x5d7 0x5d3 0x5c1 0x5a6 0x580 0x564 0x577 0x566 0x590 0x5ad 0x5ba 0x5dd 0x5e0 0x5f7 0x5c4 0x5ec 0x5db 0x5d9 0x5c5 0x5a2 0x583 0x560 0x572 0x583 0x556 0x575 0x577 0x573 0x577 0x58f 0x590 0x57a 0x59f 0x59b 0x586 0x583 0x57e 0x586 0x56b 0x593 0x55d 0x578 0x579 0x57d 0x578 0x58f 0x590 0x585 0x5a7 0x5a7 0x590 0x595 0x586 0x58c 0x574 0x5a7 0x57f 0x593 0x590 0x595 0x58a 0x5a3 0x5a0 0x58c 0x5a7 0x5ae 0x598 0x59c 0x58a 0x590 0x571 0x5a7 0x580 0x597 0x590 0x596 0x581 0x5a3 0x59c 0x597 0x5b4 0x5ba 0x5a5 0x5a9 0x58c 0x599 0x580 0x5a7 0x586 0x59d 0x599 0x5a4 0x596 0x5ab 0x5a3 0x5a1 0x5bc 0x5c2 0x5b3 0x5b7 0x5a0 0x5a2 0x586 0x5b4 0x596 0x5ab 0x5a8 0x5b1 0x5a4 0x5b9 0x5b0 0x592 0x5a8 0x5ae 0x59c 0x5a2 0x58a 0x589 0x571 0x5b4 0x59e 0x5b4 0x5ae 0x5b8 0x5aa 0x5ba 0x5b1 0x5b5 0x5ca 0x5ce 0x5bd 0x5c3 0x5ae 0x5ab 0x58f 0x5bc 0x5a6 0x5ba 0x5b5 0x5c0 0x5b2 0x5b8 0x5b8 0x5b9 0x5c7 0x5ce 0x5bc 0x5c4 0x5ad 0x59f 0x58a 0x5aa 0x59a 0x5b0 0x5ab 0x5b9 0x5a9 0x5bb 0x5ac 0x5b6 0x5c2 0x5cc 0x5ba 0x5c4 0x5ac 0x5ab 0x585 0x5b9 0x5a8 0x5c0 0x5b6 0x5c5 0x5b3 0x5c5 0x5b3 0x5c7 0x5d2 0x5dd 0x5cd 0x5d6 0x5bf 0x5bc 0x596 0x5b7 0x5b1 0x5c6 0x5c1 0x5ca 0x5b7 0x5c9 0x5ab 0x5ce 0x5d8 0x5e0 0x5d1 0x5da 0x5c2 0x5bf 0x58d 0x5c1 0x5b8 0x5cf 0x5cd 0x5d7 0x5c2 0x5d8 0x5bf 0x5cf 0x5d7 0x5e0 0x5cf 0x5d8 0x5bf 0x5bc 0x596 0x5b4 0x5b4 0x5cf 0x5c8 0x5d3 0x5bf 0x5d3 0x5b9 0x5c8 0x5cd 0x5d8 0x5c5 0x5ce 0x5b9 0x5b3 0x58d 0x5c3 0x5c3 0x5e1 0x5d9 0x5e2 0x5d0 0x5e0 0x5c3 0x5d6 0x5d9 0x5e5 0x5d3 0x5dd 0x5c6 0x5bf 0x59b 0x5bf 0x5c2 0x5e3 0x5dc 0x5e7 0x5d2 0x5e5 0x5c6 0x5d1 0x5d2 0x5de 0x5cb 0x5d8 0x5c1 0x5ba 0x593 0x5d1 0x5d2 0x5f7 0x5ef 0x5f9 0x5e7 0x5ff 0x5dd 0x5e8 0x5e9 0x5f2 0x5dd 0x5e7 0x5ce 0x5c3 0x59e 0x5c1 0x5d7 0x5fc 0x5f5 0x5ff 0x5ed 0x603 0x5e0 0x5f6 0x5fb 0x600 0x5f0 0x5fb 0x5e2 0x5d3 0x5a1 0x521 0x571 0x5b7 0x604 0x611 0x5fc 0x611 0x5ed 0x604 0x608 0x60e 0x5fa 0x605 0x5a7 0x555 0x50f 0xfffffe01 0xfffffe01 0xfffffe01>;
			PS_Config_Lmt_Open_Rawdata_P = <0xac9 0xb12 0xb64 0xbaa 0xbbc 0xbc3 0xbf2 0xb2e 0xb0b 0xb9f 0xb98 0xb92 0xb9c 0xb5f 0xb1a 0xae6 0xafe 0xb33 0xb86 0xbc1 0xbdf 0xbe6 0xc0e 0xba7 0xb6e 0xbc2 0xbbb 0xbb3 0xbbf 0xb86 0xb45 0xb30 0xb2c 0xb6a 0xbc2 0xc02 0xc21 0xc23 0xc4b 0xc17 0xbd1 0xbf2 0xbf2 0xbe6 0xbf7 0xbaa 0xb76 0xb55 0xb30 0xb7b 0xbd6 0xc13 0xc35 0xc33 0xc60 0xc28 0xbc1 0xbf6 0xbf7 0xbf0 0xbfe 0xbba 0xb83 0xb6e 0xb75 0xbae 0xc04 0xc48 0xc6b 0xc6b 0xc8d 0xc56 0xc1d 0xc2c 0xc27 0xc1d 0xc24 0xbdd 0xba7 0xb91 0xb95 0xbbf 0xc12 0xc5c 0xc86 0xc7f 0xc98 0xc66 0xc3d 0xc44 0xc3c 0xc33 0xc3c 0xbf0 0xbbc 0xbb1 0xb9b 0xbc9 0xc28 0xc6a 0xc9a 0xc95 0xcb4 0xc75 0xc52 0xc4a 0xc4e 0xc3c 0xc3d 0xbf4 0xbba 0xbae 0xbaa 0xbc2 0xc36 0xc77 0xcb4 0xcb3 0xccf 0xc8e 0xc83 0xc58 0xc74 0xc63 0xc60 0xc13 0xbda 0xbd8 0xbd4 0xc0f 0xc64 0xca5 0xceb 0xcdd 0xd03 0xcb8 0xcda 0xcbb 0xcb8 0xca9 0xc9f 0xc4f 0xc1c 0xc16 0xc00 0xc32 0xc7f 0xcc4 0xd0b 0xcfa 0xd28 0xcd9 0xce8 0xcc8 0xcbe 0xcb3 0xc9f 0xc4f 0xc17 0xc21 0xc02 0xc46 0xc70 0xcd3 0xd1c 0xd0e 0xd32 0xce9 0xd0c 0xcf2 0xcc5 0xcd6 0xcb3 0xc64 0xc28 0xc35 0xc23 0xc64 0xcaa 0xcec 0xd38 0xd2b 0xd54 0xd01 0xd2b 0xd0e 0xcfc 0xce9 0xcc9 0xc78 0xc3c 0xc52 0xc3c 0xc83 0xcd4 0xd08 0xd63 0xd59 0xd78 0xd1a 0xd3c 0xd20 0xd1c 0xcf9 0xcd7 0xc8e 0xc4d 0xc5d 0xc56 0xc9e 0xcf0 0xd15 0xd74 0xd6c 0xd91 0xd28 0xd6e 0xd4e 0xd49 0xd21 0xcf6 0xca9 0xc6d 0xc87 0xc55 0xca6 0xcfa 0xd05 0xd7b 0xd73 0xd9d 0xd2d 0xd8f 0xd63 0xd58 0xd18 0xd08 0xcad 0xc79 0xc8d 0xc6e 0xcc1 0xd11 0xd35 0xd91 0xd83 0xdba 0xd49 0xd9b 0xd6d 0xd6c 0xd40 0xd07 0xcaf 0xc7f 0xca1 0xc82 0xce5 0xd31 0xd55 0xdb0 0xdac 0xde1 0xd67 0xdc9 0xd9f 0xd97 0xd6d 0xd2e 0xcd4 0xc94 0xcbf 0xc98 0xcfc 0xd3d 0xd5e 0xdad 0xdb4 0xdeb 0xd74 0xdd2 0xda9 0xda5 0xd77 0xd26 0xcdb 0xc8c 0xcb4 0xcdb 0xc72 0xcbd 0xcc1 0xcb7 0xcbf 0xcf7 0xcfa 0xcc8 0xd1f 0xd13 0xce4 0xcdd 0xcd2 0xce2 0xca3 0xd01 0xc83 0xcc2 0xcc5 0xccd 0xcc4 0xcf9 0xcfa 0xce1 0xd31 0xd2f 0xcfc 0xd05 0xce4 0xcf2 0xcba 0xd2f 0xcd3 0xd03 0xcfc 0xd07 0xcee 0xd27 0xd20 0xcf0 0xd31 0xd40 0xd0c 0xd16 0xcee 0xcfa 0xcb1 0xd31 0xcd6 0xd0b 0xcfa 0xd08 0xcd7 0xd27 0xd16 0xd0b 0xd4e 0xd5e 0xd2d 0xd35 0xcf0 0xd11 0xcd4 0xd2f 0xce4 0xd19 0xd0f 0xd28 0xd08 0xd3b 0xd27 0xd21 0xd62 0xd6e 0xd4b 0xd55 0xd20 0xd24 0xce2 0xd50 0xd08 0xd39 0xd34 0xd47 0xd28 0xd5b 0xd44 0xcfe 0xd32 0xd40 0xd18 0xd24 0xcee 0xceb 0xcb1 0xd4e 0xd1c 0xd50 0xd42 0xd58 0xd36 0xd5e 0xd47 0xd51 0xd82 0xd8c 0xd65 0xd73 0xd42 0xd39 0xcf9 0xd60 0xd2e 0xd5c 0xd51 0xd6c 0xd4a 0xd58 0xd58 0xd5b 0xd7b 0xd8a 0xd62 0xd74 0xd3f 0xd1f 0xcee 0xd38 0xd12 0xd46 0xd3b 0xd5b 0xd35 0xd5f 0xd3c 0xd54 0xd70 0xd88 0xd5e 0xd74 0xd3c 0xd3b 0xce1 0xd59 0xd32 0xd6a 0xd54 0xd75 0xd4b 0xd77 0xd4d 0xd7b 0xd94 0xdaf 0xd89 0xd9e 0xd67 0xd60 0xd0a 0xd55 0xd49 0xd78 0xd6d 0xd82 0xd55 0xd7f 0xd3b 0xd8a 0xda2 0xdb4 0xd91 0xda8 0xd6e 0xd69 0xcf3 0xd6d 0xd58 0xd8f 0xd89 0xda1 0xd70 0xda2 0xd69 0xd8f 0xd9f 0xdb4 0xd8d 0xda4 0xd69 0xd62 0xd0a 0xd50 0xd4e 0xd8d 0xd7c 0xd97 0xd67 0xd97 0xd59 0xd7c 0xd89 0xda4 0xd77 0xd8c 0xd5b 0xd4b 0xcf5 0xd73 0xd73 0xdb7 0xda5 0xdba 0xd90 0xdb6 0xd73 0xd9e 0xda5 0xdc1 0xd97 0xdaf 0xd78 0xd69 0xd15 0xd67 0xd6e 0xdbb 0xdac 0xdc7 0xd94 0xdc1 0xd78 0xd93 0xd96 0xdb0 0xd83 0xda4 0xd6d 0xd5c 0xd01 0xd93 0xd96 0xdeb 0xdd7 0xdf1 0xdc7 0xdfd 0xdaf 0xdc8 0xdcb 0xde0 0xdaf 0xdc5 0xd8a 0xd73 0xd1c 0xd6d 0xd9f 0xdf8 0xde7 0xdff 0xdd3 0xe07 0xdb4 0xdea 0xdf3 0xe00 0xdda 0xdf5 0xdba 0xd97 0xd23 0xbf7 0xcb1 0xd57 0xe08 0xe27 0xdf8 0xe29 0xdd3 0xe08 0xe12 0xe22 0xdf2 0xe0b 0xd31 0xc71 0xbcf 0x1400 0x1400 0x1400>;
			PS_Config_Lmt_Short_Rawdata_N = <0x2774 0x2774 0x2774 0x2774 0x2774 0x2774 0x2774 0x2774 0x2774 0x2774 0x2774 0x2774 0x2774 0x2774 0x2774 0x2774 0x2774 0x2774 0x2774 0x2774 0x2774 0x2774 0x2774 0x2774 0x2774 0x2774 0x2774 0x2774 0x2774 0x2774 0x2774 0x2774 0x2774 0x2774 0x2774 0x2774 0x2774 0x2774 0x2774 0x2774 0x2774 0x2774 0x2774 0x2774 0x2774 0x2774 0x2774 0x2774 0x2774 0x2774 0x2774 0x2774 0x2774 0x2774 0x2774 0x2774 0x2774 0x2774 0x2774 0x2774 0x2774 0x2774 0x2774 0x2774 0x2774 0x2774 0x2774 0x2774 0x2774 0x2774 0x2774 0x2774 0x2774 0x2774 0x2774 0x2774 0x2774 0x2774 0x2774 0x2774 0x2774 0x2774 0x2774 0x2774 0x2774 0x2774 0x2774 0x2774 0x2774 0x2774 0x2774 0x2774 0x2774 0x2774 0x2774 0x2774 0x2774 0x2774 0x2774 0x2774 0x2774 0x2774 0x2774 0x2774 0x2774 0x2774 0x2774 0x2774 0x2774 0x2774 0x2774 0x2774 0x2774 0x2774 0x2774 0x2774 0x2774 0x2774 0x2774 0x2774 0x2774 0x2774 0x2774 0x2774 0x2774 0x2774 0x2774 0x2774 0x2774 0x2774 0x2774 0x2774 0x2774 0x2774 0x2774 0x2774 0x2774 0x2774 0x2774 0x2774 0x2774 0x2774 0x2774 0x2774 0x2774 0x2774 0x2774 0x2774 0x2774 0x2774 0x2774 0x2774 0x2774 0x2774 0x2774 0x2774 0x2774 0x2774 0x2774 0x2774 0x2774 0x2774 0x2774 0x2774 0x2774 0x2774 0x2774 0x2774 0x2774 0x2774 0x2774 0x2774 0x2774 0x2774 0x2774 0x2774 0x2774 0x2774 0x2774 0x2774 0x2774 0x2774 0x2774 0x2774 0x2774 0x2774 0x2774 0x2774 0x2774 0x2774 0x2774 0x2774 0x2774 0x2774 0x2774 0x2774 0x2774 0x2774 0x2774 0x2774 0x2774 0x2774 0x2774 0x2774 0x2774 0x2774 0x2774 0x2774 0x2774 0x2774 0x2774 0x2774 0x2774 0x2774 0x2774 0x2774 0x2774 0x2774 0x2774 0x2774 0x2774 0x2774 0x2774 0x2774 0x2774 0x2774 0x2774 0x2774 0x2774 0x2774 0x2774 0x2774 0x2774 0x2774 0x2774 0x2774 0x2774 0x2774 0x2774 0x2774 0x2774 0x2774 0x2774 0x2774 0x2774 0x2774 0x2774 0x2774 0x2774 0x2774 0x2774 0x2774 0x2774 0x2774 0x2774 0x2774 0x2774 0x2774 0x2774 0x2774 0x2774 0x2774 0x2774 0x2774 0x2774 0x2774 0x2774 0x2774 0x2774 0x2774 0x2774 0x2774 0x2774 0x2774 0x2774 0x2774 0x2774 0x2774 0x2774 0x2774 0x2774 0x2774 0x2774 0x2774 0x2774 0x2774 0x2774 0x2774 0x2774 0x2774 0x2774 0x2774 0x2774 0x2774 0x2774 0x2774 0x2774 0x2774 0x2774 0x2774 0x2774 0x2774 0x2774 0x2774 0x2774 0x2774 0x2774 0x2774 0x2774 0x2774 0x2774 0x2774 0x2774 0x2774 0x2774 0x2774 0x2774 0x2774 0x2774 0x2774 0x2774 0x2774 0x2774 0x2774 0x2774 0x2774 0x2774 0x2774 0x2774 0x2774 0x2774 0x2774 0x2774 0x2774 0x2774 0x2774 0x2774 0x2774 0x2774 0x2774 0x2774 0x2774 0x2774 0x2774 0x2774 0x2774 0x2774 0x2774 0x2774 0x2774 0x2774 0x2774 0x2774 0x2774 0x2774 0x2774 0x2774 0x2774 0x2774 0x2774 0x2774 0x2774 0x2774 0x2774 0x2774 0x2774 0x2774 0x2774 0x2774 0x2774 0x2774 0x2774 0x2774 0x2774 0x2774 0x2774 0x2774 0x2774 0x2774 0x2774 0x2774 0x2774 0x2774 0x2774 0x2774 0x2774 0x2774 0x2774 0x2774 0x2774 0x2774 0x2774 0x2774 0x2774 0x2774 0x2774 0x2774 0x2774 0x2774 0x2774 0x2774 0x2774 0x2774 0x2774 0x2774 0x2774 0x2774 0x2774 0x2774 0x2774 0x2774 0x2774 0x2774 0x2774 0x2774 0x2774 0x2774 0x2774 0x2774 0x2774 0x2774 0x2774 0x2774 0x2774 0x2774 0x2774 0x2774 0x2774 0x2774 0x2774 0x2774 0x2774 0x2774 0x2774 0x2774 0x2774 0x2774 0x2774 0x2774 0x2774 0x2774 0x2774 0x2774 0x2774 0x2774 0x2774 0x2774 0x2774 0x2774 0x2774 0x2774 0x2774 0x2774 0x2774 0x2774 0x2774 0x2774 0x2774 0x2774 0x2774 0x2774 0x2774 0x2774 0x2774 0x2774 0x2774 0x2774 0x2774 0x2774 0x2774 0x2774 0x2774 0x2774 0x2774 0x2774 0x2774 0x2774 0x2774 0x2774 0x2774 0x2774 0x2774 0x2774 0x2774 0x2774 0x2774 0x2774 0x2774 0x2774 0x2774 0x2774 0x2774 0x2774 0x2774 0x2774 0x2774 0x2774 0x2774 0x2774 0x2774 0x2774 0x2774 0x2774 0x2774 0x2774 0x2774 0x2774 0x2774 0x2774 0x2774 0x2774 0x2774 0x2774 0x2774 0x2774 0x2774 0x2774 0x2774 0x2774 0x2774 0x2774 0x2774 0x2774 0x2774 0x2774 0x2774 0x2774 0x2774 0x2774 0x2774 0x2774 0x2774 0x2774 0x2774 0x2774 0x2774 0x2774 0x2774 0x2774 0x2774 0x2774 0x2774 0x2774 0x2774 0x2774 0x2774 0x2774 0x2774 0x2774 0x2774 0x2774 0x2774 0x2774 0x2774 0x2774 0x2774 0x2774 0x2774 0x2774 0x2774 0x2774 0x2774 0x2774 0x2774 0x2774 0x2774 0x2774 0x2774 0x2774 0x2774 0x2774 0x2774 0x2774 0x2774 0x2774 0x2774 0x2710 0x2710 0x2710>;
			PS_Config_Lmt_Short_Rawdata_P = <0x36b8 0x36b8 0x36b8 0x36b8 0x36b8 0x36b8 0x36b8 0x36b8 0x36b8 0x36b8 0x36b8 0x36b8 0x36b8 0x36b8 0x36b8 0x36b8 0x36b8 0x36b8 0x36b8 0x36b8 0x36b8 0x36b8 0x36b8 0x36b8 0x36b8 0x36b8 0x36b8 0x36b8 0x36b8 0x36b8 0x36b8 0x36b8 0x36b8 0x36b8 0x36b8 0x36b8 0x36b8 0x36b8 0x36b8 0x36b8 0x36b8 0x36b8 0x36b8 0x36b8 0x36b8 0x36b8 0x36b8 0x36b8 0x36b8 0x36b8 0x36b8 0x36b8 0x36b8 0x36b8 0x36b8 0x36b8 0x36b8 0x36b8 0x36b8 0x36b8 0x36b8 0x36b8 0x36b8 0x36b8 0x36b8 0x36b8 0x36b8 0x36b8 0x36b8 0x36b8 0x36b8 0x36b8 0x36b8 0x36b8 0x36b8 0x36b8 0x36b8 0x36b8 0x36b8 0x36b8 0x36b8 0x36b8 0x36b8 0x36b8 0x36b8 0x36b8 0x36b8 0x36b8 0x36b8 0x36b8 0x36b8 0x36b8 0x36b8 0x36b8 0x36b8 0x36b8 0x36b8 0x36b8 0x36b8 0x36b8 0x36b8 0x36b8 0x36b8 0x36b8 0x36b8 0x36b8 0x36b8 0x36b8 0x36b8 0x36b8 0x36b8 0x36b8 0x36b8 0x36b8 0x36b8 0x36b8 0x36b8 0x36b8 0x36b8 0x36b8 0x36b8 0x36b8 0x36b8 0x36b8 0x36b8 0x36b8 0x36b8 0x36b8 0x36b8 0x36b8 0x36b8 0x36b8 0x36b8 0x36b8 0x36b8 0x36b8 0x36b8 0x36b8 0x36b8 0x36b8 0x36b8 0x36b8 0x36b8 0x36b8 0x36b8 0x36b8 0x36b8 0x36b8 0x36b8 0x36b8 0x36b8 0x36b8 0x36b8 0x36b8 0x36b8 0x36b8 0x36b8 0x36b8 0x36b8 0x36b8 0x36b8 0x36b8 0x36b8 0x36b8 0x36b8 0x36b8 0x36b8 0x36b8 0x36b8 0x36b8 0x36b8 0x36b8 0x36b8 0x36b8 0x36b8 0x36b8 0x36b8 0x36b8 0x36b8 0x36b8 0x36b8 0x36b8 0x36b8 0x36b8 0x36b8 0x36b8 0x36b8 0x36b8 0x36b8 0x36b8 0x36b8 0x36b8 0x36b8 0x36b8 0x36b8 0x36b8 0x36b8 0x36b8 0x36b8 0x36b8 0x36b8 0x36b8 0x36b8 0x36b8 0x36b8 0x36b8 0x36b8 0x36b8 0x36b8 0x36b8 0x36b8 0x36b8 0x36b8 0x36b8 0x36b8 0x36b8 0x36b8 0x36b8 0x36b8 0x36b8 0x36b8 0x36b8 0x36b8 0x36b8 0x36b8 0x36b8 0x36b8 0x36b8 0x36b8 0x36b8 0x36b8 0x36b8 0x36b8 0x36b8 0x36b8 0x36b8 0x36b8 0x36b8 0x36b8 0x36b8 0x36b8 0x36b8 0x36b8 0x36b8 0x36b8 0x36b8 0x36b8 0x36b8 0x36b8 0x36b8 0x36b8 0x36b8 0x36b8 0x36b8 0x36b8 0x36b8 0x36b8 0x36b8 0x36b8 0x36b8 0x36b8 0x36b8 0x36b8 0x36b8 0x36b8 0x36b8 0x36b8 0x36b8 0x36b8 0x36b8 0x36b8 0x36b8 0x36b8 0x36b8 0x36b8 0x36b8 0x36b8 0x36b8 0x36b8 0x36b8 0x36b8 0x36b8 0x36b8 0x36b8 0x36b8 0x36b8 0x36b8 0x36b8 0x36b8 0x36b8 0x36b8 0x36b8 0x36b8 0x36b8 0x36b8 0x36b8 0x36b8 0x36b8 0x36b8 0x36b8 0x36b8 0x36b8 0x36b8 0x36b8 0x36b8 0x36b8 0x36b8 0x36b8 0x36b8 0x36b8 0x36b8 0x36b8 0x36b8 0x36b8 0x36b8 0x36b8 0x36b8 0x36b8 0x36b8 0x36b8 0x36b8 0x36b8 0x36b8 0x36b8 0x36b8 0x36b8 0x36b8 0x36b8 0x36b8 0x36b8 0x36b8 0x36b8 0x36b8 0x36b8 0x36b8 0x36b8 0x36b8 0x36b8 0x36b8 0x36b8 0x36b8 0x36b8 0x36b8 0x36b8 0x36b8 0x36b8 0x36b8 0x36b8 0x36b8 0x36b8 0x36b8 0x36b8 0x36b8 0x36b8 0x36b8 0x36b8 0x36b8 0x36b8 0x36b8 0x36b8 0x36b8 0x36b8 0x36b8 0x36b8 0x36b8 0x36b8 0x36b8 0x36b8 0x36b8 0x36b8 0x36b8 0x36b8 0x36b8 0x36b8 0x36b8 0x36b8 0x36b8 0x36b8 0x36b8 0x36b8 0x36b8 0x36b8 0x36b8 0x36b8 0x36b8 0x36b8 0x36b8 0x36b8 0x36b8 0x36b8 0x36b8 0x36b8 0x36b8 0x36b8 0x36b8 0x36b8 0x36b8 0x36b8 0x36b8 0x36b8 0x36b8 0x36b8 0x36b8 0x36b8 0x36b8 0x36b8 0x36b8 0x36b8 0x36b8 0x36b8 0x36b8 0x36b8 0x36b8 0x36b8 0x36b8 0x36b8 0x36b8 0x36b8 0x36b8 0x36b8 0x36b8 0x36b8 0x36b8 0x36b8 0x36b8 0x36b8 0x36b8 0x36b8 0x36b8 0x36b8 0x36b8 0x36b8 0x36b8 0x36b8 0x36b8 0x36b8 0x36b8 0x36b8 0x36b8 0x36b8 0x36b8 0x36b8 0x36b8 0x36b8 0x36b8 0x36b8 0x36b8 0x36b8 0x36b8 0x36b8 0x36b8 0x36b8 0x36b8 0x36b8 0x36b8 0x36b8 0x36b8 0x36b8 0x36b8 0x36b8 0x36b8 0x36b8 0x36b8 0x36b8 0x36b8 0x36b8 0x36b8 0x36b8 0x36b8 0x36b8 0x36b8 0x36b8 0x36b8 0x36b8 0x36b8 0x36b8 0x36b8 0x36b8 0x36b8 0x36b8 0x36b8 0x36b8 0x36b8 0x36b8 0x36b8 0x36b8 0x36b8 0x36b8 0x36b8 0x36b8 0x36b8 0x36b8 0x36b8 0x36b8 0x36b8 0x36b8 0x36b8 0x36b8 0x36b8 0x36b8 0x36b8 0x36b8 0x36b8 0x36b8 0x36b8 0x36b8 0x36b8 0x36b8 0x36b8 0x36b8 0x36b8 0x36b8 0x36b8 0x36b8 0x36b8 0x36b8 0x36b8 0x36b8 0x36b8 0x36b8 0x36b8 0x36b8 0x36b8 0x36b8 0x36b8 0x36b8 0x36b8 0x36b8 0x36b8 0x36b8 0x36b8 0x36b8 0x36b8 0x36b8 0x36b8 0x36b8 0x36b8 0x36b8 0x36b8 0x36b8 0x36b8 0x36b8 0x36b8 0x36b8 0x36b8 0x36b8 0x36b8 0x36b8 0x36b8 0x36b8 0x36b8 0x36b8 0x36b8 0x36b8 0x36b8 0x36b8 0x36b8 0x36b8 0x36b8 0x36b8 0x36b8 0x36b8 0x36b8 0x36b8 0x36b8 0x36b8 0x36b8 0x36b8 0x36b8 0x36b8 0x36b8 0x36b8 0x36b8 0x36b8 0x36b8 0x36b8 0x36b8 0x36b8 0x36b8>;
			X_Channel = <0x10>;
			Y_Channel = <0x24>;
			compatible = "novatek-mp-criteria-5984";
		};
	};
};
